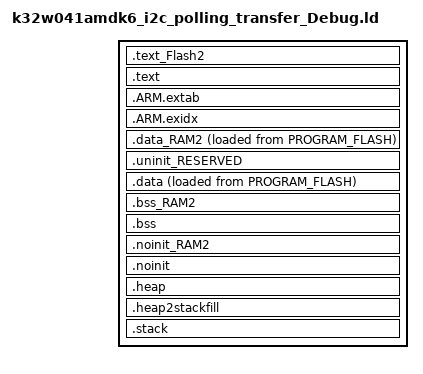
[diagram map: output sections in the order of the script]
/*
 * GENERATED FILE - DO NOT EDIT
 * Copyright 2008-2013 Code Red Technologies Ltd,
 * Copyright 2013-2026 NXP
 * SPDX-License-Identifier: BSD-3-Clause
 * Generated linker script file for K32W041AM
 * Created from linkscript.ldt by FMCreateLinkLibraries
 * Using Freemarker v2.3.30
 * MCUXpresso IDE v25.6 [Build 136] [2025-06-27] on May 16, 2026, 5:11:35 PM
 */

INCLUDE "k32w041amdk6_i2c_polling_transfer_Debug_library.ld"
INCLUDE "k32w041amdk6_i2c_polling_transfer_Debug_memory.ld"

ENTRY(ResetISR)

SECTIONS
{
     .text_Flash2 : ALIGN(4)
    {
       FILL(0xff)
        *(.text_Flash2) /* for compatibility with previous releases */
        *(.text_PROGRAM_FLASH_QSPI) /* for compatibility with previous releases */
        *(.text.$Flash2)
        *(.text.$PROGRAM_FLASH_QSPI)
        *(.text_Flash2.*) /* for compatibility with previous releases */
        *(.text_PROGRAM_FLASH_QSPI.*) /* for compatibility with previous releases */
        *(.text.$Flash2.*)
        *(.text.$PROGRAM_FLASH_QSPI.*)
        *(.rodata.$Flash2)
        *(.rodata.$PROGRAM_FLASH_QSPI)
        *(.rodata.$Flash2.*)
        *(.rodata.$PROGRAM_FLASH_QSPI.*)            } > PROGRAM_FLASH_QSPI

    /* MAIN TEXT SECTION */
    .text : ALIGN(4)
    {
        FILL(0xff)
        __vectors_start__ = ABSOLUTE(.) ;
        KEEP(*(.isr_vector))
        /* Global Section Table */
        . = ALIGN(4) ;
        __section_table_start = .;
        __data_section_table = .;
        LONG(LOADADDR(.data));
        LONG(    ADDR(.data));
        LONG(  SIZEOF(.data));
        LONG(LOADADDR(.data_RAM2));
        LONG(    ADDR(.data_RAM2));
        LONG(  SIZEOF(.data_RAM2));
        __data_section_table_end = .;
        __bss_section_table = .;
        LONG(    ADDR(.bss));
        LONG(  SIZEOF(.bss));
        LONG(    ADDR(.bss_RAM2));
        LONG(  SIZEOF(.bss_RAM2));
        __bss_section_table_end = .;
        __section_table_end = . ;
        /* End of Global Section Table */

        *(.after_vectors*)

       *(.text*)
       *(.rodata .rodata.* .constdata .constdata.*)
       . = ALIGN(4);
    } > PROGRAM_FLASH
    /*
     * for exception handling/unwind - some Newlib functions (in common
     * with C++ and STDC++) use this.
     */
    .ARM.extab : ALIGN(4)
    {
        *(.ARM.extab* .gnu.linkonce.armextab.*)
    } > PROGRAM_FLASH

    .ARM.exidx : ALIGN(4)
    {
        __exidx_start = .;
        *(.ARM.exidx* .gnu.linkonce.armexidx.*)
        __exidx_end = .;
    } > PROGRAM_FLASH
 
    _etext = .;
        
    /* DATA section for SRAM1 */

    .data_RAM2 : ALIGN(4)
    {
        FILL(0xff)
        PROVIDE(__start_data_RAM2 = .) ;
        PROVIDE(__start_data_SRAM1 = .) ;
        *(.ramfunc.$RAM2)
        *(.ramfunc.$SRAM1)
        *(.data.$RAM2)
        *(.data.$SRAM1)
        *(.data.$RAM2.*)
        *(.data.$SRAM1.*)
        . = ALIGN(4) ;
        PROVIDE(__end_data_RAM2 = .) ;
        PROVIDE(__end_data_SRAM1 = .) ;
     } > SRAM1 AT>PROGRAM_FLASH

    /* MAIN DATA SECTION */
    .uninit_RESERVED (NOLOAD) : ALIGN(4)
    {
        _start_uninit_RESERVED = .;
        KEEP(*(.bss.$RESERVED*))
       . = ALIGN(4) ;
        _end_uninit_RESERVED = .;
    } > SRAM AT> SRAM

    /* Main DATA section (SRAM) */
    .data : ALIGN(4)
    {
       FILL(0xff)
       _data = . ;
       PROVIDE(__start_data_RAM = .) ;
       PROVIDE(__start_data_SRAM = .) ;
       *(vtable)
       *(.ramfunc*)
       KEEP(*(CodeQuickAccess))
       KEEP(*(DataQuickAccess))
       *(RamFunction)
       *(.data*)
       . = ALIGN(4) ;
       _edata = . ;
       PROVIDE(__end_data_RAM = .) ;
       PROVIDE(__end_data_SRAM = .) ;
    } > SRAM AT>PROGRAM_FLASH

    /* BSS section for SRAM1 */
    .bss_RAM2 (NOLOAD) : ALIGN(4)
    {
       PROVIDE(__start_bss_RAM2 = .) ;
       PROVIDE(__start_bss_SRAM1 = .) ;
       *(.bss.$RAM2)
       *(.bss.$SRAM1)
       *(.bss.$RAM2.*)
       *(.bss.$SRAM1.*)
       . = ALIGN (. != 0 ? 4 : 1) ; /* avoid empty segment */
       PROVIDE(__end_bss_RAM2 = .) ;
       PROVIDE(__end_bss_SRAM1 = .) ;
    } > SRAM1 AT> SRAM1

    /* MAIN BSS SECTION */
    .bss (NOLOAD) : ALIGN(4)
    {
        _bss = .;
        PROVIDE(__start_bss_RAM = .) ;
        PROVIDE(__start_bss_SRAM = .) ;
        *(.bss*)
        *(COMMON)
        . = ALIGN(4) ;
        _ebss = .;
        PROVIDE(__end_bss_RAM = .) ;
        PROVIDE(__end_bss_SRAM = .) ;
        PROVIDE(end = .);
    } > SRAM AT> SRAM

    /* NOINIT section for SRAM1 */
    .noinit_RAM2 (NOLOAD) : ALIGN(4)
    {
       PROVIDE(__start_noinit_RAM2 = .) ;
       PROVIDE(__start_noinit_SRAM1 = .) ;
       *(.noinit.$RAM2)
       *(.noinit.$SRAM1)
       *(.noinit.$RAM2.*)
       *(.noinit.$SRAM1.*)
       . = ALIGN(4) ;
       PROVIDE(__end_noinit_RAM2 = .) ;
       PROVIDE(__end_noinit_SRAM1 = .) ;
    } > SRAM1 AT> SRAM1

    /* DEFAULT NOINIT SECTION */
    .noinit (NOLOAD): ALIGN(4)
    {
        _noinit = .;
        PROVIDE(__start_noinit_RAM = .) ;
        PROVIDE(__start_noinit_SRAM = .) ;
        *(.noinit*)
         . = ALIGN(4) ;
        _end_noinit = .;
       PROVIDE(__end_noinit_RAM = .) ;
       PROVIDE(__end_noinit_SRAM = .) ;        
    } > SRAM AT> SRAM

    /* Reserve and place Heap within memory map */
    _HeapSize = 0x1000;
    .heap (NOLOAD) :  ALIGN(4)
    {
        _pvHeapStart = .;
        . += _HeapSize;
        . = ALIGN(4);
        _pvHeapLimit = .;
    } > SRAM

     _StackSize = 0x1000;
     /* Reserve space in memory for Stack */
    .heap2stackfill (NOLOAD) :
    {
        . += _StackSize;
    } > SRAM
    /* Locate actual Stack in memory map */
    .stack ORIGIN(SRAM) + LENGTH(SRAM) - _StackSize - 0 (NOLOAD) :  ALIGN(4)
    {
        _vStackBase = .;
        . = ALIGN(4);
        _vStackTop = . + _StackSize;
    } > SRAM

    /* Provide basic symbols giving location and size of main text
     * block, including initial values of RW data sections. Note that
     * these will need extending to give a complete picture with
     * complex images (e.g multiple Flash banks).
     */
    _image_start = LOADADDR(.text);
    _image_end = LOADADDR(.data) + SIZEOF(.data);
    _image_size = _image_end - _image_start;
}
